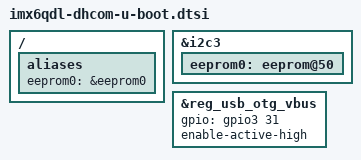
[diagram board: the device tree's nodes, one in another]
// SPDX-License-Identifier: (GPL-2.0+)
/*
 * Copyright (C) 2020 Harald Seiler <hws@denx.de>
 */

/ {
	aliases {
		eeprom0 = &eeprom0;
	};
};

&i2c3 {
	eeprom0: eeprom@50 {
	};
};

&reg_usb_otg_vbus {
	gpio = <&gpio3 31 GPIO_ACTIVE_HIGH>;
	enable-active-high;
};
